# APM32F103xx register map
File version: 1.0
CPU: CM3 r2p1, little endian, no MPU, no FPU, 4 interrupt priority bits
Registers are 32-bit, read-write, reset 0x0 unless marked. A register's access mark holds for its fields unless they carry their own. Offsets are from the block's base; [hi:lo] are bit positions; {n}, {i} and the like mark numbered series.

## TMR1 — Advanced timer
Base 0x40012C00
Same registers: TMR8 0x40013400
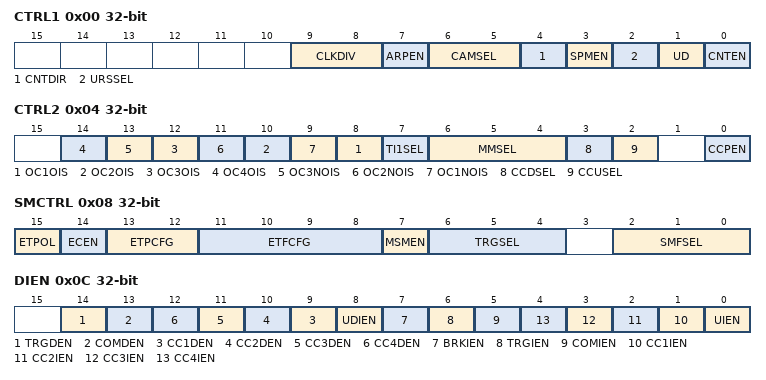
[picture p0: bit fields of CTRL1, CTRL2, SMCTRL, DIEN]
0x00 CTRL1 — control register 1
  [9:8] CLKDIV — Clock division
  [7] ARPEN — Auto-reload preload enable
  [6:5] CAMSEL — Center-aligned mode selection
  [4] CNTDIR — Direction
  [3] SPMEN — One-pulse mode
  [2] URSSEL — Update request source
  [1] UD — Update disable
  [0] CNTEN — Counter enable
0x04 CTRL2 — control register 2
  [2n+6] OC{n}OIS (n=1..4) — Output Idle state {n}
  [13] OC3NOIS — Output Idle state 3
  [11] OC2NOIS — Output Idle state 2
  [9] OC1NOIS — Output Idle state 1
  [7] TI1SEL — TI1 selection
  [6:4] MMSEL — Master mode selection
  [3] CCDSEL — Capture/compare DMA selection
  [2] CCUSEL — Capture/compare control update selection
  [0] CCPEN — Capture/compare preloaded control
0x08 SMCTRL — slave mode control register
  [15] ETPOL — External trigger polarity
  [14] ECEN — External clock enable
  [13:12] ETPCFG — External trigger prescaler
  [11:8] ETFCFG — External trigger filter
  [7] MSMEN — Master/Slave mode
  [6:4] TRGSEL — Trigger selection
  [2:0] SMFSEL — Slave mode selection
0x0C DIEN — DMA/Interrupt enable register
  [14] TRGDEN — Trigger DMA request enable
  [13] COMDEN — COM DMA request enable
  [n+8] CC{n}DEN (n=1..4) — Capture/Compare {n} DMA request enable
  [8] UDIEN — Update DMA request enable
  [7] BRKIEN — Break interrupt enable
  [6] TRGIEN — Trigger interrupt enable
  [5] COMIEN — COM interrupt enable
  [n] CC{n}IEN (n=1..4) — Capture/Compare {n} interrupt enable
  [0] UIEN — Update interrupt enable
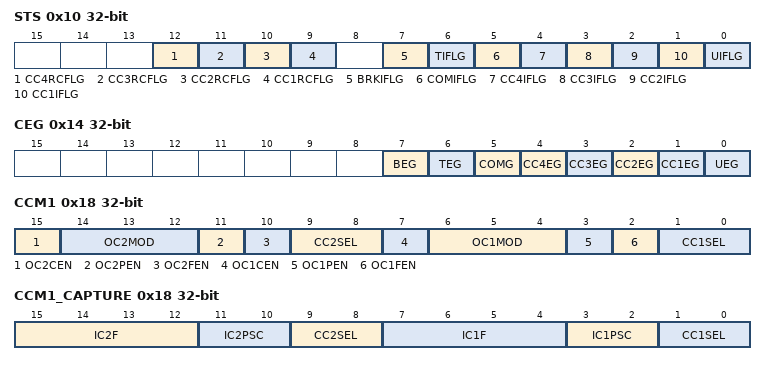
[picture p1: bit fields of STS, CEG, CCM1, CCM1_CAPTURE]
0x10 STS — status register
  [12] CC4RCFLG — Capture/Compare 4 overcapture flag
  [11] CC3RCFLG — Capture/Compare 3 overcapture flag
  [10] CC2RCFLG — Capture/compare 2 overcapture flag
  [9] CC1RCFLG — Capture/Compare 1 overcapture flag
  [7] BRKIFLG — Break interrupt flag
  [6] TIFLG — Trigger interrupt flag
  [5] COMIFLG — COM interrupt flag
  [4] CC4IFLG — Capture/Compare 4 interrupt flag
  [3] CC3IFLG — Capture/Compare 3 interrupt flag
  [2] CC2IFLG — Capture/Compare 2 interrupt flag
  [1] CC1IFLG — Capture/compare 1 interrupt flag
  [0] UIFLG — Update interrupt flag
0x14 CEG wo — event generation register
  [7] BEG — Break generation
  [6] TEG — Trigger generation
  [5] COMG — Capture/Compare control update generation
  [n] CC{n}EG (n=1..4) — Capture/compare {n} generation
  [0] UEG — Update generation
0x18 CCM1 — capture/compare mode register 1 (Compare mode)
  [15] OC2CEN — Output Compare 2 clear enable
  [14:12] OC2MOD — Output Compare 2 mode
  [11] OC2PEN — Output Compare 2 preload enable
  [10] OC2FEN — Output Compare 2 fast enable
  [9:8] CC2SEL — Capture/Compare 2 selection
  [7] OC1CEN — Output Compare 1 clear enable
  [6:4] OC1MOD — Output Compare 1 mode
  [3] OC1PEN — Output Compare 1 preload enable
  [2] OC1FEN — Output Compare 1 fast enable
  [1:0] CC1SEL — Capture/Compare 1 selection
0x18 CCM1_CAPTURE (alternate view of CCM1) — capture/compare mode register 1 (Capture mode)
  [15:12] IC2F — Input capture 2 filter
  [11:10] IC2PSC — Input capture 2 prescaler
  [9:8] CC2SEL — Capture/Compare 2 selection
  [7:4] IC1F — Input capture 1 filter
  [3:2] IC1PSC — Input capture 1 prescaler
  [1:0] CC1SEL — Capture/Compare 1 selection
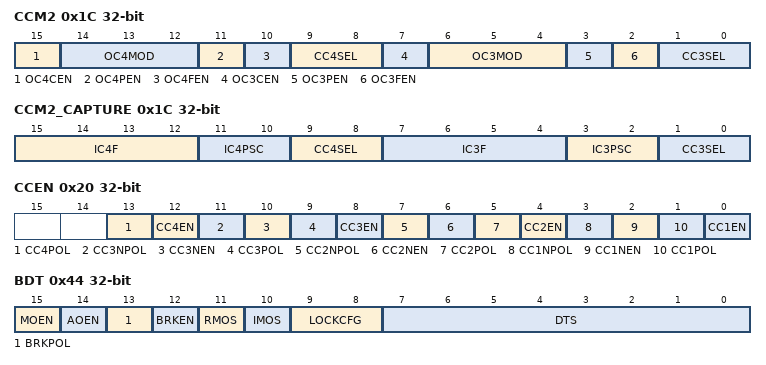
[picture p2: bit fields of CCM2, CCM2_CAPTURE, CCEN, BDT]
0x1C CCM2 — capture/compare mode register 2 (Compare mode)
  [15] OC4CEN — Output compare 4 clear enable
  [14:12] OC4MOD — Output compare 4 mode
  [11] OC4PEN — Output compare 4 preload enable
  [10] OC4FEN — Output compare 4 fast enable
  [9:8] CC4SEL — Capture/Compare 4 selection
  [7] OC3CEN — Output compare 3 clear enable
  [6:4] OC3MOD — Output compare 3 mode
  [3] OC3PEN — Output compare 3 preload enable
  [2] OC3FEN — Output compare 3 fast enable
  [1:0] CC3SEL — Capture/Compare 3 selection
0x1C CCM2_CAPTURE (alternate view of CCM2) — capture/compare mode register 2 (Capture mode)
  [15:12] IC4F — Input capture 4 filter
  [11:10] IC4PSC — Input capture 4 prescaler
  [9:8] CC4SEL — Capture/Compare 4 selection
  [7:4] IC3F — Input capture 3 filter
  [3:2] IC3PSC — Input capture 3 prescaler
  [1:0] CC3SEL — Capture/compare 3 selection
0x20 CCEN — capture/compare enable register
  [13] CC4POL — Capture/Compare 3 output Polarity
  [4n-4] CC{n}EN (n=1..4) — Capture/Compare {n} output enable
  [11] CC3NPOL — Capture/Compare 3 output Polarity
  [10] CC3NEN — Capture/Compare 3 complementary output enable
  [9] CC3POL — Capture/Compare 3 output Polarity
  [7] CC2NPOL — Capture/Compare 2 output Polarity
  [6] CC2NEN — Capture/Compare 2 complementary output enable
  [5] CC2POL — Capture/Compare 2 output Polarity
  [3] CC1NPOL — Capture/Compare 1 output Polarity
  [2] CC1NEN — Capture/Compare 1 complementary output enable
  [1] CC1POL — Capture/Compare 1 output Polarity
0x24 CNT — counter
  [15:0] CNT — counter value
0x28 PSC — prescaler
  [15:0] PSC — Prescaler value
0x2C AUTORLD — auto-reload register
  [15:0] AUTORLD — Auto-reload value
0x30 REPCNT — Repeat count register
  [15:0] REPCNT — Repetition Counter Value
{0x30+4i} CC{i} (i=1..4) — capture/compare register {i}
  [15:0] CC{i} — Capture/Compare {i} value
0x44 BDT — Brake and dead zone registers
  [15] MOEN — Main output enable
  [14] AOEN — Automatic output enable
  [13] BRKPOL — Break polarity
  [12] BRKEN — Break enable
  [11] RMOS — Off-state selection for Run mode
  [10] IMOS — Off-state selection for Idle mode
  [9:8] LOCKCFG — Lock configuration
  [7:0] DTS — Dead-time generator setup
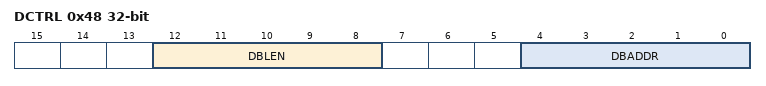
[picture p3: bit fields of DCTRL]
0x48 DCTRL — DMA control register
  [12:8] DBLEN — DMA burst length
  [4:0] DBADDR — DMA base address
0x4C DMADDR — Consecutive DMA addresses
  [15:0] DMADDR — DMA register for burst accesses

## TMR2 — General purpose timer
Base 0x40000000
Same registers: TMR3 0x40000400, TMR4 0x40000800, TMR5 0x40000C00
Registers as TMR1, without REPCNT, BDT; these are added or differ:
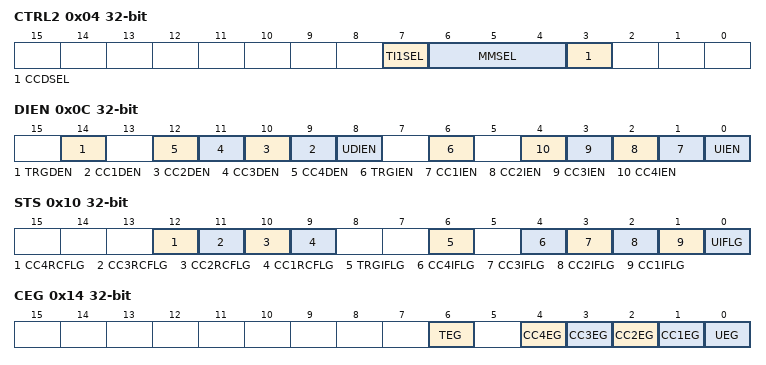
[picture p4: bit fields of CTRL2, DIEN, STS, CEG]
0x04 CTRL2 — control register 2
  [7] TI1SEL — TI1 selection
  [6:4] MMSEL — Master mode selection
  [3] CCDSEL — Capture/compare DMA selection
0x0C DIEN — DMA/Interrupt enable register
  [14] TRGDEN — Trigger DMA request enable
  [n+8] CC{n}DEN (n=1..4) — Capture/Compare {n} DMA request enable
  [8] UDIEN — Update DMA request enable
  [6] TRGIEN — Trigger interrupt enable
  [n] CC{n}IEN (n=1..4) — Capture/Compare {n} interrupt enable
  [0] UIEN — Update interrupt enable
0x10 STS — status register
  [12] CC4RCFLG — Capture/Compare 4 overcapture flag
  [11] CC3RCFLG — Capture/Compare 3 overcapture flag
  [10] CC2RCFLG — Capture/compare 2 overcapture flag
  [9] CC1RCFLG — Capture/Compare 1 overcapture flag
  [6] TRGIFLG — Trigger interrupt flag
  [4] CC4IFLG — Capture/Compare 4 interrupt flag
  [3] CC3IFLG — Capture/Compare 3 interrupt flag
  [2] CC2IFLG — Capture/Compare 2 interrupt flag
  [1] CC1IFLG — Capture/compare 1 interrupt flag
  [0] UIFLG — Update interrupt flag
0x14 CEG wo — event generation register
  [6] TEG — Trigger generation
  [n] CC{n}EG (n=1..4) — Capture/compare {n} generation
  [0] UEG — Update generation
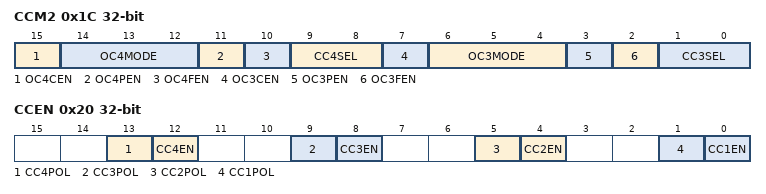
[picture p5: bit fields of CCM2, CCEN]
0x1C CCM2 — capture/compare mode register 2 (Compare mode)
  [15] OC4CEN — Output compare 4 clear enable
  [14:12] OC4MODE — Output compare 4 mode
  [11] OC4PEN — Output compare 4 preload enable
  [10] OC4FEN — Output compare 4 fast enable
  [9:8] CC4SEL — Capture/Compare 4 selection
  [7] OC3CEN — Output compare 3 clear enable
  [6:4] OC3MODE — Output compare 3 mode
  [3] OC3PEN — Output compare 3 preload enable
  [2] OC3FEN — Output compare 3 fast enable
  [1:0] CC3SEL — Capture/Compare 3 selection
0x20 CCEN — capture/compare enable register
  [13] CC4POL — Capture/Compare 3 output Polarity
  [4n-4] CC{n}EN (n=1..4) — Capture/Compare {n} output enable
  [9] CC3POL — Capture/Compare 3 output Polarity
  [5] CC2POL — Capture/Compare 2 output Polarity
  [1] CC1POL — Capture/Compare 1 output Polarity
